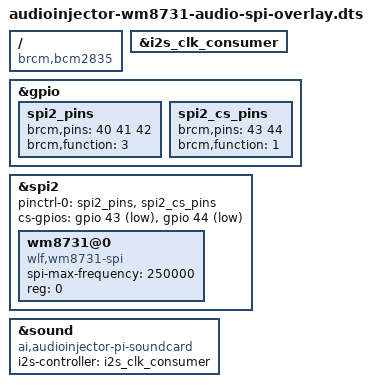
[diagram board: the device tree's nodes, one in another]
// Definitions for audioinjector.net audio add on soundcard
/dts-v1/;
/plugin/;

/ {
	compatible = "brcm,bcm2835";

	fragment@0 {
		target = <&i2s_clk_consumer>;
		__overlay__ {
			status = "okay";
		};
	};

	
	fragment@1 {
		target = <&gpio>;
		__overlay__ {
			spi2_pins: spi2_pins {
				brcm,pins = <40 41 42>;
				brcm,function = <3>;
			};
			spi2_cs_pins: spi2_cs_pins {
				brcm,pins = <43 44>;
				brcm,function = <1>;
			};
		};
	};

	fragment@2 {
		target = <&spi2>;
		__overlay__ {
			#address-cells = <1>;
			#size-cells = <0>;
			
			pinctrl-names = "default";
			pinctrl-0 = <&spi2_pins &spi2_cs_pins>;
			cs-gpios = <&gpio 43 1>, <&gpio 44 1>;
			status = "okay";

			wm8731@0 {
				#sound-dai-cells = <0>;
				compatible = "wlf,wm8731-spi";
				spi-max-frequency = <250000>;
				reg = <0>;
				status = "okay";
			};
		};
	};

	fragment@3 {
		target = <&sound>;
		__overlay__ {
			compatible = "ai,audioinjector-pi-soundcard";
			i2s-controller = <&i2s_clk_consumer>;
			status = "okay";
		};
	};

};

